# S6E1B3xF register map
Vendor: Cypress; File version: 2.1
CPU: CM0PLUS r0p1, little endian, no MPU, no FPU, 2 interrupt priority bits
Registers are 8-bit, read-write, reset 0x0 unless marked. A register's access mark holds for its fields unless they carry their own. Offsets are from the block's base; [hi:lo] are bit positions.

## SMCIF0 — Smart Card Interface 0 Registers
Base 0x4003C900
Same registers: SMCIF1 0x4003C980
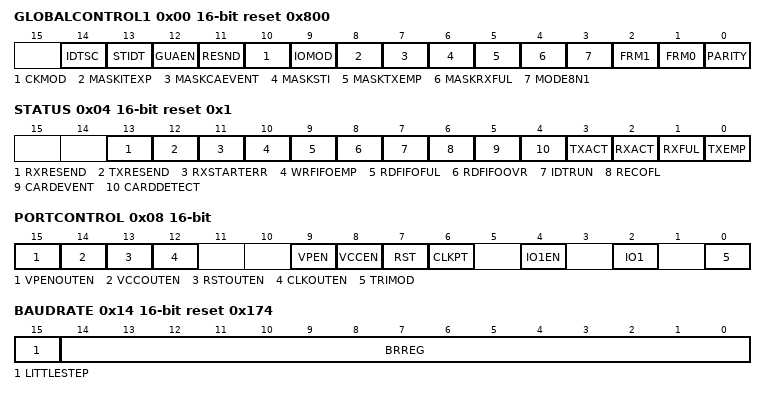
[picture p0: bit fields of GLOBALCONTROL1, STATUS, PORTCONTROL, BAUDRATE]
0x00 GLOBALCONTROL1 16-bit reset 0x800 — Global Control Register 1 [HW]
  [14] IDTSC — Idle timer clock select bit
  [13] STIDT — Start idle timer bit
  [12] GUAEN — Guard timer enable bit
  [11] RESND — Transmiter and receiver resend function enable bit
  [10] CKMOD — Clock generation mode select bit
  [9] IOMOD — Data generation mode select bit
  [8] MASKITEXP — Idle timer expired interrupt enable bit
  [7] MASKCAEVENT — Card event detect interrupt enable bit
  [6] MASKSTI — Start bit detect interrupt enable bit
  [5] MASKTXEMP — Transmit data register empty interrupt enable bit
  [4] MASKRXFUL — Receive data register full interrupt enable bit
  [3] MODE8N1 — Clock generation mode select bit
  [2] FRM1 — Data frame coding style select bit
  [1] FRM0 — Clock generation mode select bit
  [0] PARITY — Odd/Even parity select bit
0x04 STATUS 16-bit ro reset 0x1 — Status Register [HW]
  [13] RXRESEND — Receiver resend flag bit
  [12] TXRESEND — Transmitter resend flag bit
  [11] RXSTARTERR — Received start bit error flag bit
  [10] WRFIFOEMP — Write FIFO empty flag bit
  [9] RDFIFOFUL — Read FIFO full flag bit
  [8] RDFIFOOVR — Read FIFO overflow flag
  [7] IDTRUN — Idle timer running flag
  [6] RECOFL — Received data register overflow flag
  [5] CARDEVENT — Card event flag
  [4] CARDDETECT — Level on ICx_CIN input pin
  [3] TXACT — Transmitter status flag
  [2] RXACT — Receiver status flag
  [1] RXFUL — Received data register status flag
  [0] TXEMP — Transmit data register status flag
0x08 PORTCONTROL 16-bit — Port Control Register [HW]
  [15] VPENOUTEN — ICx_VPEN output enable bit
  [14] VCCOUTEN — ICx_VCC output enable bit
  [13] RSTOUTEN — ICx_RST output enable bit
  [12] CLKOUTEN — ICx_CLK output enable bit
  [9] VPEN — ICx_VPEN output value
  [8] VCCEN — ICx_VCC output value
  [7] RST — ICx_RST output value
  [6] CLKPT — ICx_CLK output value
  [4] IO1EN — ICx_DATA output enable control bit
  [2] IO1 — Level on ICx_DATA pin
  [0] TRIMOD — ICx_DATA output enable generation mode select bit
0x0C DATA 16-bit — Data Register [HW]
  [8:0] DATA — Transmit/Received data
0x10 CARDCLOCK 16-bit — Card Clock Frequency Register [HW]
  [15:0] CLKDIVIDER — Card clock frequency divider
0x14 BAUDRATE 16-bit reset 0x174 — Baud Rate Register [HW]
  [15] LITTLESTEP — Little step bit for baud rate
  [14:0] BRREG — Baud rate register bits
0x18 GUARDTIMER 16-bit — Guard Timer Register [HW]
  [7:0] GTREG — Guard time in ETUs
0x1C IDLETIMER 16-bit — Idle Timer Register [HW]
  [15:0] IDTREG — Reload value for idle timer
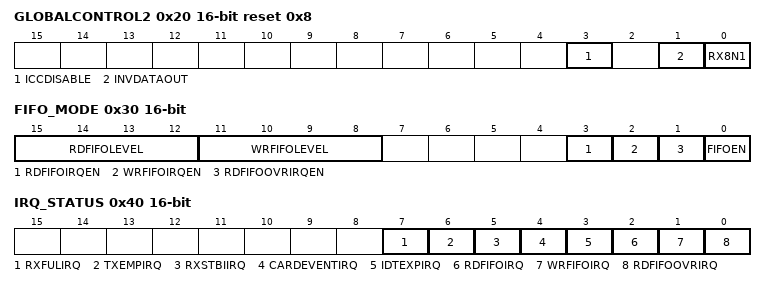
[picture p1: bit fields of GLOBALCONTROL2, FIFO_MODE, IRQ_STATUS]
0x20 GLOBALCONTROL2 16-bit wo reset 0x8 — Global Control Register 2 [HW]
  [3] ICCDISABLE rw — ICC disable/enable bit
  [1] INVDATAOUT rw — Output inversion enable bit
  [0] RX8N1 rw — Serial data output enable bit
0x24 DATA_FIFO 16-bit — FIFO Access Register [HW]
  [8:0] DATA — Transmit/Received data
0x28 FIFO_LEVEL_READ 16-bit ro — Read FIFO Level Register [HW]
  [15:0] FIFORDLEVEL — Read FIFO level
0x2C FIFO_LEVEL_WRITE 16-bit ro — Write FIFO Level Register [HW]
  [15:0] FIFOWRLEVEL — Read FIFO level
0x30 FIFO_MODE 16-bit — FIFO Mode Register [HW]
  [15:12] RDFIFOLEVEL — Read FIFO level
  [11:8] WRFIFOLEVEL — Write FIFO level
  [3] RDFIFOIRQEN — Read FIFO full interrupt enable bit
  [2] WRFIFOIRQEN — Write FIFO empty interrupt enable bit
  [1] RDFIFOOVRIRQEN — Read FIFO overflow interrupt enable bit
  [0] FIFOEN — FIFO enable bit
0x34 FIFO_CLEAR_MSB_WRITE 16-bit — Write FIFO Clear Register [HW]
  [0] CLRWRFIFO — Write FIFO clear bit
0x38 FIFO_CLEAR_MSB_READ 16-bit — Read FIFO Clear Register [HW]
  [0] CLRRDFIFO — Read FIFO clear bit
0x40 IRQ_STATUS 16-bit ro — Interrupt Status Register [HW]
  [7] RXFULIRQ — Received data register full interrupt flag bit
  [6] TXEMPIRQ — Transmit data register empty interrupt flag bit
  [5] RXSTBIIRQ — Received start bit interrupt flag bit
  [4] CARDEVENTIRQ — Card event interrupt flag bit
  [3] IDTEXPIRQ — Idle timer expired interrupt flag bit
  [2] RDFIFOIRQ — Read FIFO full interrupt flag bit
  [1] WRFIFOIRQ — Write FIFO empty interrupt flag bit
  [0] RDFIFOOVRIRQ — Read FIFO overflow interrupt flag bit
